# nrf54h20_engb_sysctrl register map
Vendor: Nordic Semiconductor; Series: nRF54h; File version: 1
Registers are 32-bit, read-write, reset 0x0 unless marked. A register's access mark holds for its fields unless they carry their own. Offsets are from the block's base; [hi:lo] are bit positions; lines under a group give offsets from that group; 'fields as' and 'values as' point back to an identical list.

## CLOCK
Base 0x5F950000
0x00 TASKS_LFCLKSTART wo — Start the LF clock source
  [0] TASKS_LFCLKSTART
    1=Trigger task
0x04 TASKS_LFCLKSTOP wo — Clear the TASKS_CLKSTART request
  [0] TASKS_LFCLKSTOP
    1=Trigger task
0x100 EVENTS_LFCLKSTARTED — LF clock started
  [0] EVENTS_LFCLKSTARTED
    0=NotGenerated (Event not generated); 1=Generated (Event generated)
0x104 EVENTS_LFCLKSRCCHANGED — LF clock source changed
  [0] EVENTS_LFCLKSRCCHANGED
    values as EVENTS_LFCLKSTARTED.EVENTS_LFCLKSTARTED
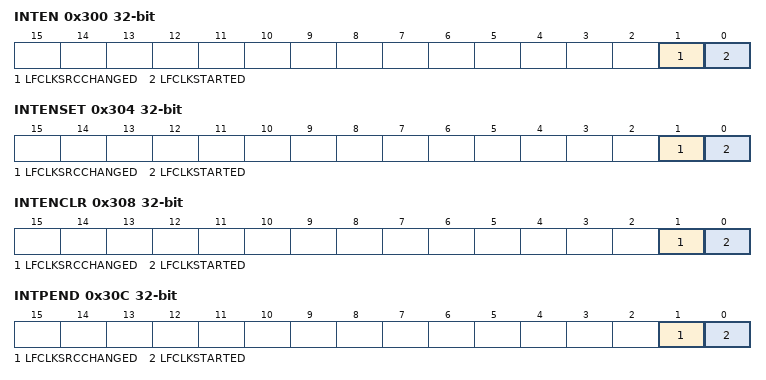
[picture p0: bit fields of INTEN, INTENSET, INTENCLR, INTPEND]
0x300 INTEN — Enable or disable interrupt
  [1] LFCLKSRCCHANGED — Enable or disable interrupt for event LFCLKSRCCHANGED
    0=Disabled; 1=Enabled
  [0] LFCLKSTARTED — Enable or disable interrupt for event LFCLKSTARTED
    0=Disabled; 1=Enabled
0x304 INTENSET — Enable interrupt
  [1] LFCLKSRCCHANGED — Write '1' to enable interrupt for event LFCLKSRCCHANGED
    on read: 0=Disabled (Read: Disabled); 1=Enabled (Read: Enabled) | on write: 1=Set (Enable)
  [0] LFCLKSTARTED — Write '1' to enable interrupt for event LFCLKSTARTED
    values as LFCLKSRCCHANGED
0x308 INTENCLR — Disable interrupt
  [1] LFCLKSRCCHANGED — Write '1' to disable interrupt for event LFCLKSRCCHANGED
    on read: 0=Disabled (Read: Disabled); 1=Enabled (Read: Enabled) | on write: 1=Clear (Disable)
  [0] LFCLKSTARTED — Write '1' to disable interrupt for event LFCLKSTARTED
    values as LFCLKSRCCHANGED
0x30C INTPEND ro — Pending interrupts
  [1] LFCLKSRCCHANGED — Read pending status of interrupt for event LFCLKSRCCHANGED
    on read: 0=NotPending (Read: Not pending); 1=Pending (Read: Pending)
  [0] LFCLKSTARTED — Read pending status of interrupt for event LFCLKSTARTED
    values as LFCLKSRCCHANGED
0x400 LFCLKSTAT group — Unspecified
  0x00 RUN ro — Status indicating that TASKS_START task has been triggered for LF clock.
    [0] STATUS — Clock start task triggered or not
      0=NotTriggered (Task not triggered); 1=Triggered (Task triggered)
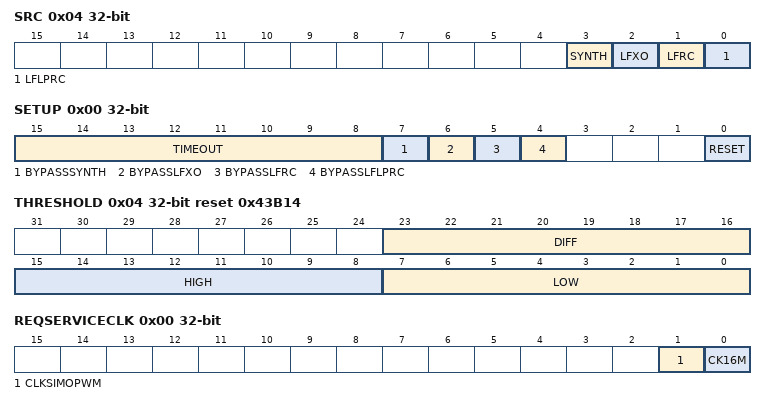
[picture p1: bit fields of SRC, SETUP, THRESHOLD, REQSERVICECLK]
  0x04 SRC ro — Status indicating which clock source is running for LF clock
    [3] SYNTH — Synthesized LF clock status
      0=NotActive (SYNTH is not active); 1=Active (SYNTH is active)
    [2] LFXO — LFXO clock status
      0=NotActive (LFXO is not active); 1=Active (LFXO is active)
    [1] LFRC — LFRC clock status
      0=NotActive (LFRC is not active); 1=Active (LFRC is active)
    [0] LFLPRC — LFLPRC clock status
      0=NotActive (LFLPRC is not active); 1=Active (LFLPRC is active)
0x440 LFCLKCTRL group — Unspecified
  0x00 ALWAYSRUN reset 0x1 — Force the LF clock source and tree running always
    [0] FORCE — Force the clock always running
      0=Automatic clock control enabled; 1=AlwaysRun (Clock always running)
  0x04 SRC reset 0x8 — Select the clock source for LF clock
    [3] SYNTH — Synthesized LF as clock source
      0=UnSelected (SYNTH is unselected); 1=Selected (SYNTH is selected)
    [2] LFXO — Select LFXO as clock source
      0=UnSelected (LFXO is unselected); 1=Selected (LFXO is selected)
    [1] LFRC — Select LFRC as clock source
      0=UnSelected (LFRC is unselected); 1=Selected (LFRC is selected)
    [0] LFLPRC — Select LFLPRC as clock source
      0=UnSelected (LFLPRC is unselected); 1=Selected (LFLPRC is selected)
0x450 CONFIG group — Unspecified
  0x00 SETUP — Peripheral setup
    [15:8] TIMEOUT — Timeout for the clock alignment process
    [7] BYPASSSYNTH — Enable bypass SYNTH
      0=Disabled; 1=Enabled
    [6] BYPASSLFXO — Enable bypass LFXO
      0=Disabled; 1=Enabled
    [5] BYPASSLFRC — Enable bypass LFRC
      0=Disabled; 1=Enabled
    [4] BYPASSLFLPRC — Enable bypass LFLPRC
      0=Disabled; 1=Enabled
    [0] RESET — Reset the peripheral
      0=Disabled; 1=Enabled
  0x04 THRESHOLD reset 0x43B14 — Threshold limit while clock switching
    [23:16] DIFF — Threshold difference while clock switching
    [15:8] HIGH — Threshold high limit while clock switching
    [7:0] LOW — Threshold low limit while clock switching
0x500 BACKDOORS group — Unspecified
  0x00 REQSERVICECLK — Backdoor request for service clocks
    [1] CLKSIMOPWM — Request SIMO PWM service clock
      0=NotRequested (Unspecified); 1=Requested (Unspecified)
    [0] CK16M — Request 16M service clock
      0=NotRequested (Unspecified); 1=Requested (Unspecified)
